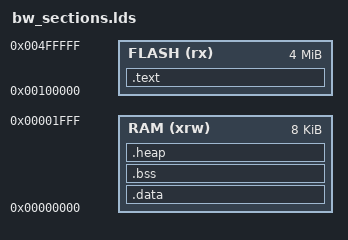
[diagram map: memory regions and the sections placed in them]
MEMORY
{
    FLASH (rx) : ORIGIN = 0x00100000, LENGTH = 0x400000
    RAM (xrw) : ORIGIN = 0x00000000, LENGTH = 0x2000
}
SECTIONS {
    .text :
    {
        . = ALIGN(4);
        *(.text)
        *(.text*)
        *(.rodata)
        *(.rodata*)
        *(.srodata)
        *(.srodata*)
        . = ALIGN(4);
        _etext = .;
        _sidata = _etext;
    } >FLASH
    .data : AT ( _sidata )
    {
        . = ALIGN(4);
        _sdata = .;
        _ram_start = .;
        . = ALIGN(4);
        *(.data)
        *(.data*)
        . = ALIGN(8);
        PROVIDE( __global_pointer$ = . + 0x800 );
        *(.sdata)
        *(.sdata*)
        . = ALIGN(4);
        _edata = .;
    } >RAM
    .bss :
    {
        . = ALIGN(4);
        _sbss = .;
        *(.bss)
        *(.bss*)
        *(.sbss)
        *(.sbss*)
        *(COMMON)
        . = ALIGN(4);
        _ebss = .;
        _end = .;
    } >RAM
    .heap :
    {
        . = ALIGN(4);
        _heap_start = .;
    } >RAM
}
